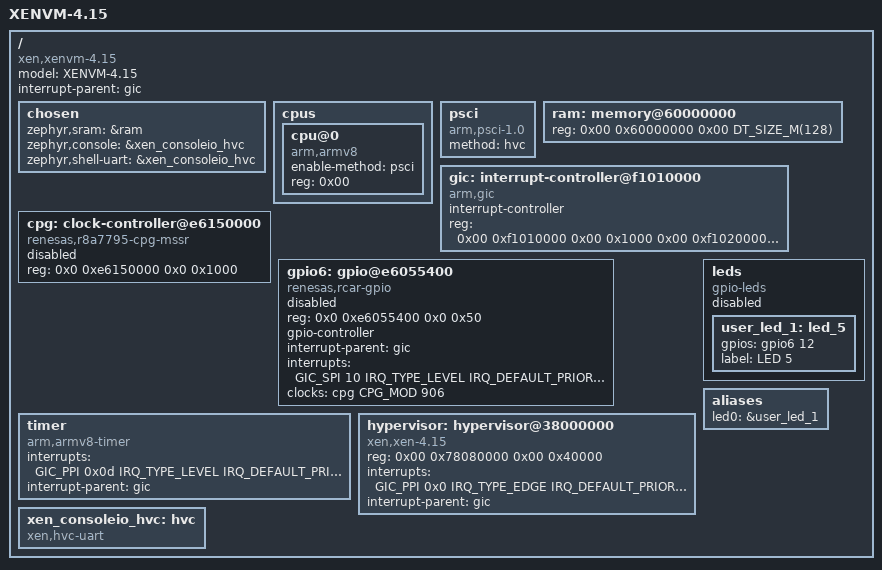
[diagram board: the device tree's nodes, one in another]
/*
 * Copyright (c) 2020 EPAM Systems
 *
 * SPDX-License-Identifier: Apache-2.0
 *
 * This file was created by running
 *
 * # LIBXL_DEBUG_DUMP_DTB=domu-libxl.dtb xl create zephyr.conf
 *
 * decompiling resulting domu-libxl.dtb and then manually aligning it
 * with zephyr requirements.
 */

/dts-v1/;

#include <mem.h>
#include <arm64/armv8-a.dtsi>
#include <zephyr/dt-bindings/interrupt-controller/arm-gic.h>
#include <zephyr/dt-bindings/clock/renesas_cpg_mssr.h>
#include <zephyr/dt-bindings/gpio/gpio.h>

/ {
	model = "XENVM-4.15";
	compatible = "xen,xenvm-4.15", "xen,xenvm";
	interrupt-parent = <&gic>;
	#address-cells = <0x02>;
	#size-cells = <0x02>;

	chosen {
		zephyr,sram = &ram;
		zephyr,console = &xen_consoleio_hvc;
		zephyr,shell-uart = &xen_consoleio_hvc;
	};

	cpus {
		#address-cells = <0x01>;
		#size-cells = <0x00>;

		cpu@0 {
			device_type = "cpu";
			compatible = "arm,armv8";
			enable-method = "psci";
			reg = <0x00>;
		};
	};

	psci {
		compatible = "arm,psci-1.0", "arm,psci-0.2", "arm,psci";
		method = "hvc";
	};

	ram: memory@60000000 {
		device_type = "mmio-sram";
		reg = <0x00 0x60000000 0x00 DT_SIZE_M(128)>;
	};

	gic: interrupt-controller@f1010000 {
		compatible = "arm,gic";
		#interrupt-cells = <0x04>;
		#address-cells = <0x00>;
		interrupt-controller;
		reg = <0x00 0xf1010000 0x00 0x1000 0x00 0xf1020000 0x00 0x2000>;
	};

	cpg: clock-controller@e6150000 {
			compatible = "renesas,r8a7795-cpg-mssr";
			reg = <0x0 0xe6150000 0x0 0x1000>;
			#clock-cells = <2>;
			status = "disabled";
	};

	gpio6: gpio@e6055400 {
			compatible = "renesas,rcar-gpio";
			reg = <0x0 0xe6055400 0x0 0x50>;
			#gpio-cells = <2>;
			gpio-controller;
			interrupt-parent = <&gic>;
			interrupts = <GIC_SPI 10 IRQ_TYPE_LEVEL IRQ_DEFAULT_PRIORITY>;
			clocks = <&cpg CPG_MOD 906>;
			status = "disabled";
	};

	timer {
		compatible = "arm,armv8-timer";
		interrupts = <GIC_PPI 0x0d IRQ_TYPE_LEVEL IRQ_DEFAULT_PRIORITY
			      GIC_PPI 0x0e IRQ_TYPE_LEVEL IRQ_DEFAULT_PRIORITY
			      GIC_PPI 0x0b IRQ_TYPE_LEVEL IRQ_DEFAULT_PRIORITY>;
		interrupt-parent = <&gic>;
	};

	hypervisor: hypervisor@38000000 {
		compatible = "xen,xen-4.15", "xen,xen";
		reg = <0x00 0x78080000 0x00 0x40000>;
		interrupts = <GIC_PPI 0x0 IRQ_TYPE_EDGE IRQ_DEFAULT_PRIORITY>;
		interrupt-parent = <&gic>;
	};

	xen_consoleio_hvc: hvc {
		compatible = "xen,hvc-uart";
		status = "okay";
	};

	leds {
		compatible = "gpio-leds";
		user_led_1: led_5 {
			gpios = <&gpio6 12 GPIO_ACTIVE_HIGH>;
			label = "LED 5";
		};
		status = "disabled";
	};

	aliases {
		led0 = &user_led_1;
	};
};
